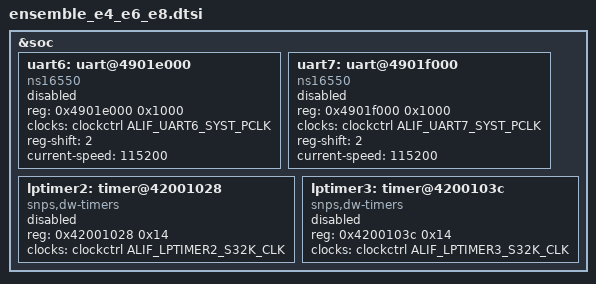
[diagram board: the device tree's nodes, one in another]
/*
 * SPDX-FileCopyrightText: Copyright Alif Semiconductor
 * SPDX-License-Identifier: Apache-2.0
 */

/*
 * Peripherals shared by the E4, E6 and E8 Ensemble SoCs that are additional
 * to the minimum common subset (see ensemble_common.dtsi). As with the common
 * layer, interrupt routing is intentionally kept out of this file and lives in
 * the controller-specific ensemble_e4_e6_e8_{nvic,gic}_irq.dtsi files.
 */

#include <alif/ensemble/common/ensemble_common.dtsi>

&soc {
	uart6: uart@4901e000 {
		compatible = "ns16550";
		reg = <0x4901e000 0x1000>;
		clocks = <&clockctrl ALIF_UART6_SYST_PCLK>;
		reg-shift = <2>;
		current-speed = <115200>;
		status = "disabled";
	};

	uart7: uart@4901f000 {
		compatible = "ns16550";
		reg = <0x4901f000 0x1000>;
		clocks = <&clockctrl ALIF_UART7_SYST_PCLK>;
		reg-shift = <2>;
		current-speed = <115200>;
		status = "disabled";
	};

	/* The E1C series only implements LPTIMER0 and LPTIMER1 */
	lptimer2: timer@42001028 {
		compatible = "snps,dw-timers";
		reg = <0x42001028 0x14>;
		clocks = <&clockctrl ALIF_LPTIMER2_S32K_CLK>;
		status = "disabled";
	};

	lptimer3: timer@4200103c {
		compatible = "snps,dw-timers";
		reg = <0x4200103c 0x14>;
		clocks = <&clockctrl ALIF_LPTIMER3_S32K_CLK>;
		status = "disabled";
	};
};
